# STM32L162xDx register map
File version: 1.0
Registers are 32-bit, read-write, reset 0x0 unless marked. A register's access mark holds for its fields unless they carry their own. Offsets are from the block's base; [hi:lo] are bit positions; {n}, {i} and the like mark numbered series; 'fields as' and 'values as' point back to an identical list.

## GPIOA — General Purpose IO
Base 0x40020000
Same registers: GPIOB 0x40020400, GPIOC 0x40020800, GPIOD 0x40020C00, GPIOE 0x40021000, GPIOH 0x40021400, GPIOF 0x40021800, GPIOG 0x40021C00
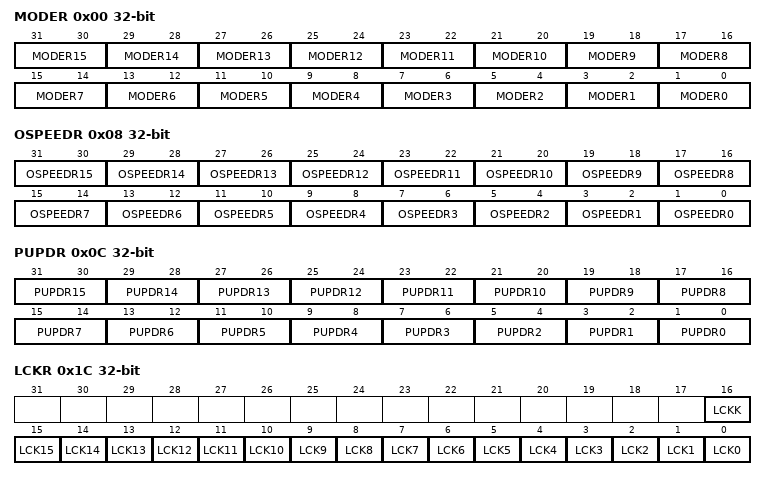
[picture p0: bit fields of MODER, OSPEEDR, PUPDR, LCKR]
0x00 MODER — GPIO port mode register
  [2n+1:2n] MODER{n} (n=0..15)
0x04 OTYPER — GPIO port output type register
0x08 OSPEEDR — GPIO port output speed register
  [2n+1:2n] OSPEEDR{n} (n=0..15)
0x0C PUPDR — GPIO port pull-up/pull-down register
  [2n+1:2n] PUPDR{n} (n=0..15)
0x10 IDR — GPIO port input data register
0x14 ODR — GPIO port output data register
0x18 BSRR — GPIO port bit set/reset registerBSRR
0x1C LCKR — GPIO port configuration lock register
  [16] LCKK, [n] LCK{n} (n=0..15)
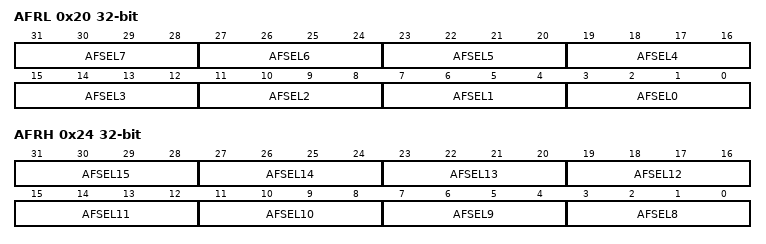
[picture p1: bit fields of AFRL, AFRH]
0x20 AFRL — GPIO alternate function register
  [4n+3:4n] AFSEL{n} (n=0..7)
0x24 AFRH — GPIO alternate function register
  [4n-29:4n-32] AFSEL{n} (n=8..15)
0x28 BRR — GPIO bit reset register

## CRC — CRC calculation unit
Base 0x40023000
0x00 DR — CRC Data register
  [31:0] DR — Data register bits
0x04 IDR 8-bit — CRC Independent data register
  [7:0] IDR — General-purpose 8-bit data register bits
0x08 CR — CRC Control register
  [0] RESET — RESET bit

## FLASH — FLASH Registers
Base 0x40023C00
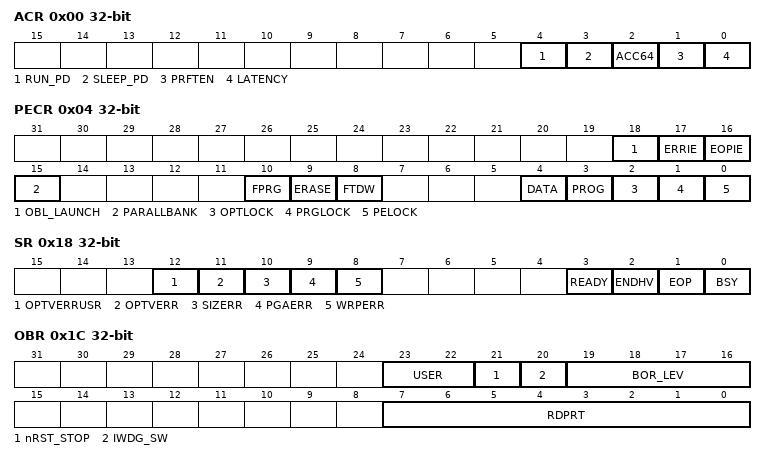
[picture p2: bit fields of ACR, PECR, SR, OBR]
0x00 ACR — Access control register
  [4] RUN_PD — Flash mode during RUN mode
  [3] SLEEP_PD — Flash mode during sleep mode
  [2] ACC64 — Access 64 bits
  [1] PRFTEN — Prefetch Buffer Enable
  [0] LATENCY
    0=FLASH Zero Latency cycle; 1=FLASH One Latency cycle
0x04 PECR — Program/erase control register
  [18] OBL_LAUNCH — Launch the option byte loading
  [17] ERRIE — Error interrupt
  [16] EOPIE — End of programming interrupt
  [15] PARALLBANK — Parallel Bank mode
  [10] FPRG — Fast Page/Half Page programming mode
  [9] ERASE — Page erasing mode
  [8] FTDW — Fixed Time Data write for Word/Half Word/Byte programming
  [4] DATA — Data matrix selection
  [3] PROG — Program matrix selection
  [2] OPTLOCK — Option byte matrix Lock
  [1] PRGLOCK — Program matrix Lock
  [0] PELOCK — FLASH_PECR and Flash data Lock
0x08 PDKEYR — Power down key register
  [31:0] PDKEYR — FLASH_PEC and data matrix Key
0x0C PEKEYR — Program/erase key register
  [31:0] PEKEYR — FLASH_PEC and data matrix Key
0x10 PRGKEYR — Program memory key register
  [31:0] PRGKEYR — Program matrix Key
0x14 OPTKEYR — Option byte key register
  [31:0] OPTKEYR — Option bytes matrix Key
0x18 SR — Status register
  [12] OPTVERRUSR — Option User validity error
  [11] OPTVERR — Option validity error
  [10] SIZERR — Size error
  [9] PGAERR — Programming Alignment Error
  [8] WRPERR — Write protected error
  [3] READY — Flash ready after low power mode
  [2] ENDHV — End of high voltage
  [1] EOP — End Of Programming
  [0] BSY — Busy
0x1C OBR — Option byte register
  [23:22] USER — User Option Bytes
  [21] nRST_STOP
  [20] IWDG_SW
  [19:16] BOR_LEV — BOR_LEV[3:0] Brown Out Reset Threshold Level
  [7:0] RDPRT — Read Protection
0x20 WRPR1 — Write protection register 1
  [31:0] WRP — Write Protect sectors 0 to 31
0x80 WRPR2 — Write protection register 2
  [15:0] WRP — Write Protect sectors 32 to 47
0x84 WRPR3 — Write protection register 3
  [31:0] WRP — Write Protect sectors 64 to 95
0x88 WRPR4 — Write protection register 4
  [15:0] WRP — Write Protect sectors 96 to 111

## DMA1
Base 0x40026000
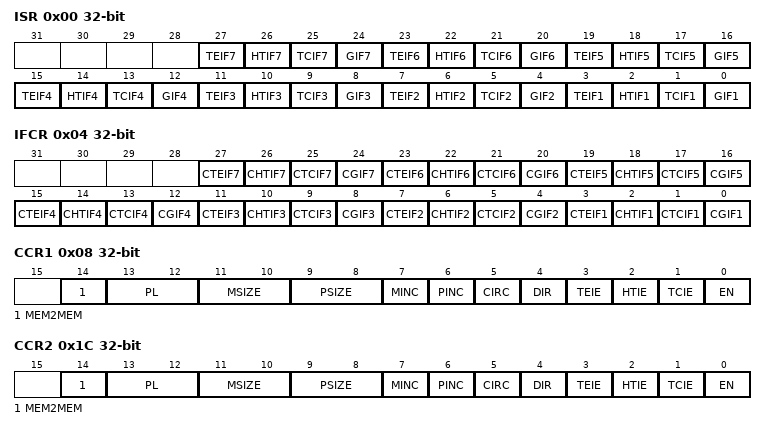
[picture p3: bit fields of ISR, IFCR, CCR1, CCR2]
0x00 ISR — DMA interrupt status register
  [4n-1] TEIF{n} (n=1..7) — Channel {n} Transfer Error flag
  [4n-2] HTIF{n} (n=1..7) — Channel {n} Half Transfer flag
  [4n-3] TCIF{n} (n=1..7) — Channel {n} Transfer Complete flag
  [4n-4] GIF{n} (n=1..7) — Channel {n} Global interrupt flag
0x04 IFCR — DMA interrupt flag clear register
  [4n-1] CTEIF{n} (n=1..7) — Channel {n} Transfer Error clear
  [4n-2] CHTIF{n} (n=1..7) — Channel {n} Half Transfer clear
  [4n-3] CTCIF{n} (n=1..7) — Channel {n} Transfer Complete clear
  [4n-4] CGIF{n} (n=1..7) — Channel {n} Global interrupt clear
0x08 CCR1 — DMA channel x configuration register
  [14] MEM2MEM — Memory to memory mode
  [13:12] PL — PL[1:0] bits(Channel Priority level)
  [11:10] MSIZE — MSIZE[1:0] bits (Memory size)
  [9:8] PSIZE — PSIZE[1:0] bits (Peripheral size)
  [7] MINC — Memory increment mode
  [6] PINC — Peripheral increment mode
  [5] CIRC — Circular mode
  [4] DIR — Data transfer direction
  [3] TEIE — Transfer error interrupt enable
  [2] HTIE — Half Transfer interrupt enable
  [1] TCIE — Transfer complete interrupt enable
  [0] EN — Channel enable
0x0C CNDTR1 — DMA channel x number of data register
  [15:0] NDT — Number of data to Transfer
0x10 CPAR1 — DMA channel x peripheral address register
  [31:0] PA — Peripheral Address
{0x0+0x14*i} CMAR{i} (i=1..7) — DMA channel x memory address register
  [31:0] MA — Memory Address
0x1C CCR2 — DMA channel x configuration register
  fields as CCR1
0x20 CNDTR2 — DMA channel x number of data register
  [15:0] NDT — Number of data to Transfer
0x24 CPAR2 — DMA channel x peripheral address register
  [31:0] PA — Peripheral Address
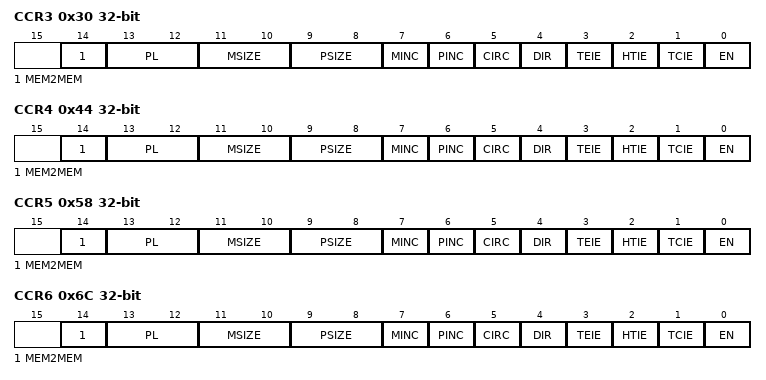
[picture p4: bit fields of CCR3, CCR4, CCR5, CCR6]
0x30 CCR3 — DMA channel x configuration register
  fields as CCR1
0x34 CNDTR3 — DMA channel x number of data register
  [15:0] NDT — Number of data to Transfer
0x38 CPAR3 — DMA channel x peripheral address register
  [31:0] PA — Peripheral Address
0x44 CCR4 — DMA channel x configuration register
  fields as CCR1
0x48 CNDTR4 — DMA channel x number of data register
  [15:0] NDT — Number of data to Transfer
0x4C CPAR4 — DMA channel x peripheral address register
  [31:0] PA — Peripheral Address
0x58 CCR5 — DMA channel x configuration register
  fields as CCR1
0x5C CNDTR5 — DMA channel x number of data register
  [15:0] NDT — Number of data to Transfer
0x60 CPAR5 — DMA channel x peripheral address register
  [31:0] PA — Peripheral Address
0x6C CCR6 — DMA channel x configuration register
  fields as CCR1
0x70 CNDTR6 — DMA channel x number of data register
  [15:0] NDT — Number of data to Transfer
0x74 CPAR6 — DMA channel x peripheral address register
  [31:0] PA — Peripheral Address
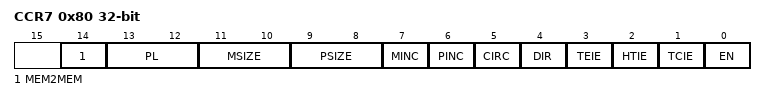
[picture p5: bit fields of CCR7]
0x80 CCR7 — DMA channel x configuration register
  fields as CCR1
0x84 CNDTR7 — DMA channel x number of data register
  [15:0] NDT — Number of data to Transfer
0x88 CPAR7 — DMA channel x peripheral address register
  [31:0] PA — Peripheral Address

## DMA2
Base 0x40026400
Registers as DMA1, without CCR6, CNDTR6, CPAR6, CMAR6, CCR7, CNDTR7, CPAR7, CMAR7.

## AES — AES hardware accelerator
Base 0x50060000
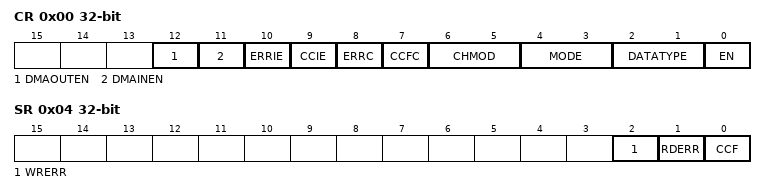
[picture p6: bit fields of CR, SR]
0x00 CR — AES control register
  [12] DMAOUTEN — DMA Enable managing the data output phase
  [11] DMAINEN — DMA ENable managing the data input phase
  [10] ERRIE — Error Interrupt Enable
  [9] CCIE — Computation Complete Interrupt Enable
  [8] ERRC — Error Clear
  [7] CCFC — Computation Complete Flag Clear
  [6:5] CHMOD — AES Chaining Mode
  [4:3] MODE — AES Mode Of Operation
  [2:1] DATATYPE — Data type selection
  [0] EN — AES Enable
0x04 SR — AES status register
  [2] WRERR — Write Error Flag
  [1] RDERR — Read Error Flag
  [0] CCF — Computation Complete Flag
0x08 DINR — AES data input register
  [15:0] DINR — AES Data Input Register
0x0C DOUTR — AES data output register
  [15:0] DOUTR — AES Data Output Register
{0x10+4i} KEYR{i} (i=0..3) — AES key register {i}
  [15:0] KEYR{i} — AES Key Register {i}
{0x20+4i} IVR{i} (i=0..3) — AES initialization vector register {i}
  [15:0] IVR{i} — AES Initialization Vector Register {i}

## DBGMCU — Debug MCU
Base 0xE0042000
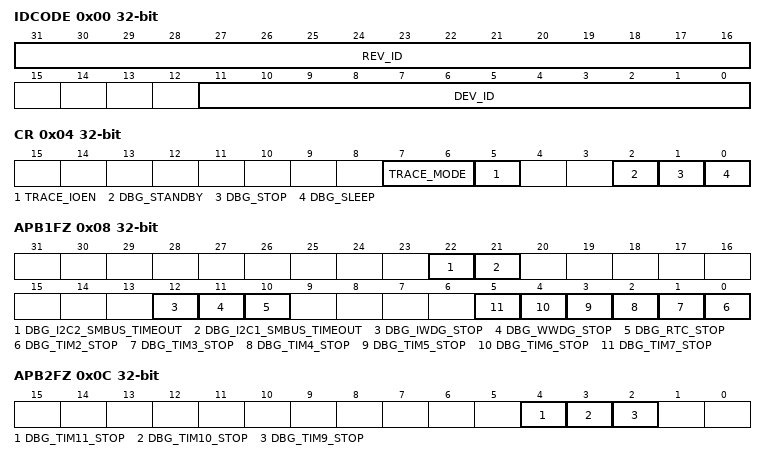
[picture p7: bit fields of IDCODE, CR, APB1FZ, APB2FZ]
0x00 IDCODE — MCU device ID code
  [31:16] REV_ID — REV_ID[15:0] bits (Revision Identifier)
  [11:0] DEV_ID — Device Identifier
0x04 CR — Debug MCU configuration register
  [7:6] TRACE_MODE — TRACE_MODE[1:0] bits (Trace Pin Assignment Control)
  [5] TRACE_IOEN — Trace Pin Assignment Control
  [2] DBG_STANDBY — Debug Standby mode
  [1] DBG_STOP — Debug Stop Mode
  [0] DBG_SLEEP — Debug Sleep Mode
0x08 APB1FZ — Debug MCU APB1 freeze register
  [22] DBG_I2C2_SMBUS_TIMEOUT — SMBUS timeout mode stopped when Core is halted
  [21] DBG_I2C1_SMBUS_TIMEOUT — SMBUS timeout mode stopped when Core is halted
  [12] DBG_IWDG_STOP — Debug Independent Watchdog stopped when Core is halted
  [11] DBG_WWDG_STOP — Debug Window Watchdog stopped when Core is halted
  [10] DBG_RTC_STOP — RTC Counter stopped when Core is halted
  [n-2] DBG_TIM{n}_STOP (n=2..7) — TIM{n} counter stopped when core is halted
0x0C APB2FZ — Debug MCU APB2 freeze register
  [4] DBG_TIM11_STOP — TIM11 counter stopped when core is halted
  [3] DBG_TIM10_STOP — TIM10 counter stopped when core is halted
  [2] DBG_TIM9_STOP — TIM9 counter stopped when core is halted
